AUTOSAR XML (schema 00047)
package /ARPackage
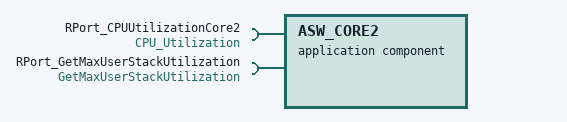
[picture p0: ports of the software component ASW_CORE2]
  application sw component type ASW_CORE2
    require port RPort_CPUUtilizationCore2: required-interface=CPU_Utilization
    require port RPort_GetMaxUserStackUtilization: required-interface=GetMaxUserStackUtilization
    behavior SwcInternalBehavior
      7 x timing event:
        TimingEvent_0: start-on-event=RE_CORE2_SWC, period=0.005
        TimingEvent_1: start-on-event=GMAIN_CORE2_1ms, period=0.001
        TimingEvent_2: start-on-event=GMAIN_CORE2_2ms, period=0.002
        TimingEvent_3: start-on-event=GMAIN_CORE2_5ms, period=0.005
        TimingEvent_4: start-on-event=GMAIN_CORE2_10ms, period=0.01
        TimingEvent_5: start-on-event=GMAIN_CORE2_100ms, period=0.1
        TimingEvent_6: start-on-event=GMAIN_CORE2_200ms, period=0.2
      7 x runnable:
        RE_CORE2_SWC: symbol=RE_CORE2_SWC_func
          sync call SynchronousServerCallPoint_0: operation=RPort_CPUUtilizationCore2.CPU_Utilization
          sync call SynchronousServerCallPoint_1: operation=RPort_GetMaxUserStackUtilization.GetMaxUserStackUtilization
        GMAIN_CORE2_1ms: symbol=GMAIN_CORE2_1ms_func
        GMAIN_CORE2_2ms: symbol=GMAIN_CORE2_2ms_func
        GMAIN_CORE2_5ms: symbol=GMAIN_CORE2_5ms_func
        GMAIN_CORE2_10ms: symbol=GMAIN_CORE2_10ms_func
        GMAIN_CORE2_100ms: symbol=GMAIN_CORE2_100ms_func
        GMAIN_CORE2_200ms: symbol=GMAIN_CORE2_200ms_func
